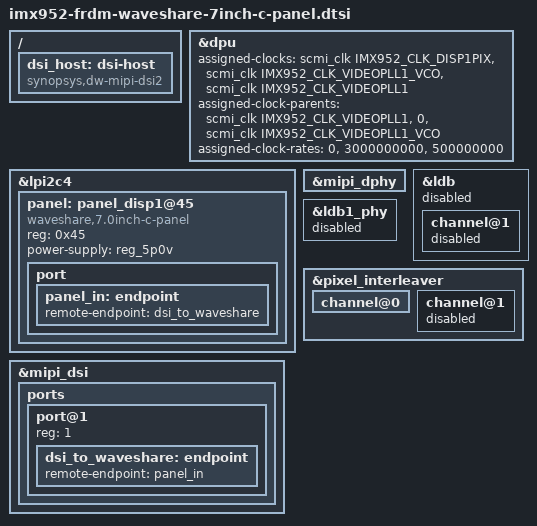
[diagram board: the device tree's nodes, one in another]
// SPDX-License-Identifier: (GPL-2.0+ OR MIT)
/*
 * Copyright 2026 NXP
 */

/ {
	dsi_host: dsi-host {
		compatible = "synopsys,dw-mipi-dsi2";
		status = "okay";
	};
};

&dpu {
	assigned-clocks = <&scmi_clk IMX952_CLK_DISP1PIX>,
			  <&scmi_clk IMX952_CLK_VIDEOPLL1_VCO>,
			  <&scmi_clk IMX952_CLK_VIDEOPLL1>;
	assigned-clock-parents = <&scmi_clk IMX952_CLK_VIDEOPLL1>,
			  <0>,
			  <&scmi_clk IMX952_CLK_VIDEOPLL1_VCO>;
	assigned-clock-rates = <0>, <3000000000>, <500000000>;
};

&lpi2c4 {
	#address-cells = <1>;
	#size-cells = <0>;

	panel: panel_disp1@45 {
		compatible = "waveshare,7.0inch-c-panel";
		reg = <0x45>;
		power-supply = <&reg_5p0v>;

		port {
			panel_in: endpoint {
				remote-endpoint = <&dsi_to_waveshare>;
			};
		};
	};
};

&mipi_dsi {
	status = "okay";

	ports {
		#address-cells = <1>;
		#size-cells = <0>;

		port@1 {
			reg = <1>;

			dsi_to_waveshare: endpoint {
				remote-endpoint = <&panel_in>;
			};
		};
	};
};

&mipi_dphy {
	status = "okay";
};

&ldb {
	status = "disabled";

	channel@1 {
		status = "disabled";
		/delete-node/ display-timings;
	};
};

&ldb1_phy {
	status = "disabled";
};

&pixel_interleaver {
	status = "okay";

	channel@0 {
		status = "okay";
	};

	channel@1 {
		status = "disabled";
	};
};
